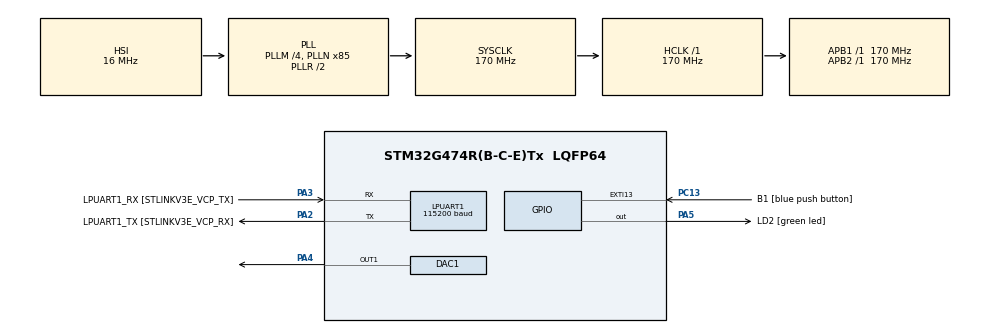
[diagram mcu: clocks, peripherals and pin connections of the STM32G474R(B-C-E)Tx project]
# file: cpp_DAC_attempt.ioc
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DAC1.DAC_SignedFormat-DAC_OUT1=DISABLE
DAC1.DAC_Trigger_OUT1-DAC_OUT1=DAC_TRIGGER_T6_TRGO
Dma.DAC1_CH1.0.Direction=DMA_MEMORY_TO_PERIPH
Dma.DAC1_CH1.0.EventEnable=DISABLE
Dma.DAC1_CH1.0.Instance=DMA1_Channel1
Dma.DAC1_CH1.0.MemDataAlignment=DMA_MDATAALIGN_HALFWORD
Dma.DAC1_CH1.0.MemInc=DMA_MINC_ENABLE
Dma.DAC1_CH1.0.Mode=DMA_CIRCULAR
Dma.DAC1_CH1.0.PeriphDataAlignment=DMA_PDATAALIGN_HALFWORD
Dma.DAC1_CH1.0.PeriphInc=DMA_PINC_DISABLE
Dma.DAC1_CH1.0.Polarity=HAL_DMAMUX_REQ_GEN_RISING
Dma.DAC1_CH1.0.Priority=DMA_PRIORITY_LOW
Dma.DAC1_CH1.0.RequestNumber=1
Dma.DAC1_CH1.0.SignalID=NONE
Dma.DAC1_CH1.0.SyncEnable=DISABLE
Dma.DAC1_CH1.0.SyncPolarity=HAL_DMAMUX_SYNC_NO_EVENT
Dma.DAC1_CH1.0.SyncRequestNumber=1
Dma.DAC1_CH1.0.SyncSignalID=NONE
Dma.Request0=DAC1_CH1
LPUART1.BaudRate=115200
LPUART1.WordLength=UART_WORDLENGTH_8B
Mcu.Family=STM32G4
Mcu.Name=STM32G474R(B-C-E)Tx
Mcu.Package=LQFP64
NVIC.DMA1_Channel1_IRQn=true\:0\:0\:false\:false\:true\:false\:true
NVIC.EXTI15_10_IRQn=true\:0\:0\:false\:false\:true\:true\:true
NVIC.PriorityGroup=NVIC_PRIORITYGROUP_4
NVIC.TIM6_DAC_IRQn=true\:0\:0\:false\:false\:true\:true\:true
PA13.GPIO_Label=T_SWDIO
PA13.Mode=Serial_Wire
PA13.Signal=SYS_JTMS-SWDIO
PA14.GPIO_Label=T_SWCLK
PA14.Mode=Serial_Wire
PA14.Signal=SYS_JTCK-SWCLK
PA2.GPIO_Label=LPUART1_TX [STLINKV3E_VCP_RX]
PA2.Mode=Asynchronous
PA2.Signal=LPUART1_TX
PA3.GPIO_Label=LPUART1_RX [STLINKV3E_VCP_TX]
PA3.Mode=Asynchronous
PA3.Signal=LPUART1_RX
PA4.Signal=COMP_DAC11_group
PA5.GPIO_Label=LD2 [green led]
PA5.Signal=GPIO_Output
PB3.GPIO_Label=T_SWO
PB3.Signal=SYS_JTDO-SWO
PC13.GPIO_Label=B1 [blue push button]
PC13.Signal=GPXTI13
PC14-OSC32_IN.Mode=LSE-External-Oscillator
PC14-OSC32_IN.Signal=RCC_OSC32_IN
PC15-OSC32_OUT.Mode=LSE-External-Oscillator
PC15-OSC32_OUT.Signal=RCC_OSC32_OUT
PF0-OSC_IN.Mode=HSE-External-Oscillator
PF0-OSC_IN.Signal=RCC_OSC_IN
PF1-OSC_OUT.Mode=HSE-External-Oscillator
PF1-OSC_OUT.Signal=RCC_OSC_OUT
ProjectManager.HeapSize=0x200
ProjectManager.StackSize=0x400
ProjectManager.TargetToolchain=STM32CubeIDE
RCC.ADC12Freq_Value=170000000
RCC.ADC345Freq_Value=170000000
RCC.AHBFreq_Value=170000000
RCC.APB1Freq_Value=170000000
RCC.APB1TimFreq_Value=170000000
RCC.APB2Freq_Value=170000000
RCC.APB2TimFreq_Value=170000000
RCC.CortexFreq_Value=170000000
RCC.EXTERNAL_CLOCK_VALUE=12288000
RCC.HCLKFreq_Value=170000000
RCC.HSE_VALUE=24000000
RCC.HSI48_VALUE=48000000
RCC.HSI_VALUE=16000000
RCC.PLLM=RCC_PLLM_DIV4
RCC.PLLN=85
RCC.RTCClockSelection=RCC_RTCCLKSOURCE_LSE
RCC.SYSCLKFreq_VALUE=170000000
RCC.SYSCLKSource=RCC_SYSCLKSOURCE_PLLCLK
RCC.USBFreq_Value=170000000
RCC.VCOOutputFreq_Value=340000000
SH.COMP_DAC11_group.0=DAC1_OUT1,DAC_OUT1
TIM6.TIM_MasterOutputTrigger=TIM_TRGO_UPDATE
VP_SYS_VS_DBSignals.Mode=DisableDeadBatterySignals
VP_TIM6_VS_ClockSourceINT.Mode=Enable_Timer
board=NUCLEO-G474RE

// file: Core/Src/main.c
/* USER CODE BEGIN Header */
/**
  ******************************************************************************
  * @file           : main.c
  * @brief          : Main program body
  ******************************************************************************
  * @attention
  *
  * <h2><center>&copy; Copyright (c) 2021 STMicroelectronics.
  * All rights reserved.</center></h2>
  *
  * This software component is licensed by ST under BSD 3-Clause license,
  * the "License"; You may not use this file except in compliance with the
  * License. You may obtain a copy of the License at:
  *                        opensource.org/licenses/BSD-3-Clause
  *
  ******************************************************************************
  */
/* USER CODE END Header */
#include "main.h"

DAC_HandleTypeDef hdac1;
DMA_HandleTypeDef hdma_dac1_ch1;

UART_HandleTypeDef hlpuart1;

TIM_HandleTypeDef htim6;

/* USER CODE BEGIN PV */
const uint32_t HIGH_ARRAY[12] = {0, 100, 200, 300, 400, 500, 600, 700, 800, 900, 1000, 10000};
const uint16_t LOW_ARRAY[1] = {0};

/* USER CODE END PV */

void SystemClock_Config(void);
static void MX_GPIO_Init(void);
static void MX_DMA_Init(void);
static void MX_LPUART1_UART_Init(void);
static void MX_DAC1_Init(void);
static void MX_TIM6_Init(void);

int main(void)
{

  /* MCU Configuration--------------------------------------------------------*/

  /* Reset of all peripherals, Initializes the Flash interface and the Systick. */
  HAL_Init();

  /* Configure the system clock */
  SystemClock_Config();

  /* Initialize all configured peripherals */
  MX_GPIO_Init();
  MX_DMA_Init();
  MX_LPUART1_UART_Init();
  MX_DAC1_Init();
  MX_TIM6_Init();
  /* USER CODE BEGIN 2 */
  HAL_TIM_Base_Start(&htim6);
  HAL_DAC_Start(&hdac1,DAC_CHANNEL_1);
  HAL_DAC_Start_DMA(&hdac1, DAC_CHANNEL_1, (uint32_t*)HIGH_ARRAY, 32, DAC_ALIGN_12B_R);
  /* USER CODE END 2 */

  /* Infinite loop */
  while (1)
  {

  }
}

void SystemClock_Config(void)
{
  RCC_OscInitTypeDef RCC_OscInitStruct = {0};
  RCC_ClkInitTypeDef RCC_ClkInitStruct = {0};
  RCC_PeriphCLKInitTypeDef PeriphClkInit = {0};

  /** Configure the main internal regulator output voltage
  */
  HAL_PWREx_ControlVoltageScaling(PWR_REGULATOR_VOLTAGE_SCALE1_BOOST);
  /** Initializes the RCC Oscillators according to the specified parameters
  * in the RCC_OscInitTypeDef structure.
  */
  RCC_OscInitStruct.OscillatorType = RCC_OSCILLATORTYPE_HSI;
  RCC_OscInitStruct.HSIState = RCC_HSI_ON;
  RCC_OscInitStruct.HSICalibrationValue = RCC_HSICALIBRATION_DEFAULT;
  RCC_OscInitStruct.PLL.PLLState = RCC_PLL_ON;
  RCC_OscInitStruct.PLL.PLLSource = RCC_PLLSOURCE_HSI;
  RCC_OscInitStruct.PLL.PLLM = RCC_PLLM_DIV4;
  RCC_OscInitStruct.PLL.PLLN = 85;
  RCC_OscInitStruct.PLL.PLLP = RCC_PLLP_DIV2;
  RCC_OscInitStruct.PLL.PLLQ = RCC_PLLQ_DIV2;
  RCC_OscInitStruct.PLL.PLLR = RCC_PLLR_DIV2;
  if (HAL_RCC_OscConfig(&RCC_OscInitStruct) != HAL_OK)
  {
    Error_Handler();
  }
  /** Initializes the CPU, AHB and APB buses clocks
  */
  RCC_ClkInitStruct.ClockType = RCC_CLOCKTYPE_HCLK|RCC_CLOCKTYPE_SYSCLK
                              |RCC_CLOCKTYPE_PCLK1|RCC_CLOCKTYPE_PCLK2;
  RCC_ClkInitStruct.SYSCLKSource = RCC_SYSCLKSOURCE_PLLCLK;
  RCC_ClkInitStruct.AHBCLKDivider = RCC_SYSCLK_DIV1;
  RCC_ClkInitStruct.APB1CLKDivider = RCC_HCLK_DIV1;
  RCC_ClkInitStruct.APB2CLKDivider = RCC_HCLK_DIV1;

  if (HAL_RCC_ClockConfig(&RCC_ClkInitStruct, FLASH_LATENCY_4) != HAL_OK)
  {
    Error_Handler();
  }
  /** Initializes the peripherals clocks
  */
  PeriphClkInit.PeriphClockSelection = RCC_PERIPHCLK_LPUART1;
  PeriphClkInit.Lpuart1ClockSelection = RCC_LPUART1CLKSOURCE_PCLK1;
  if (HAL_RCCEx_PeriphCLKConfig(&PeriphClkInit) != HAL_OK)
  {
    Error_Handler();
  }
}

static void MX_DAC1_Init(void)
{

  DAC_ChannelConfTypeDef sConfig = {0};

  /** DAC Initialization
  */
  hdac1.Instance = DAC1;
  if (HAL_DAC_Init(&hdac1) != HAL_OK)
  {
    Error_Handler();
  }
  /** DAC channel OUT1 config
  */
  sConfig.DAC_HighFrequency = DAC_HIGH_FREQUENCY_INTERFACE_MODE_AUTOMATIC;
  sConfig.DAC_DMADoubleDataMode = DISABLE;
  sConfig.DAC_SignedFormat = DISABLE;
  sConfig.DAC_SampleAndHold = DAC_SAMPLEANDHOLD_DISABLE;
  sConfig.DAC_Trigger = DAC_TRIGGER_T6_TRGO;
  sConfig.DAC_Trigger2 = DAC_TRIGGER_NONE;
  sConfig.DAC_OutputBuffer = DAC_OUTPUTBUFFER_ENABLE;
  sConfig.DAC_ConnectOnChipPeripheral = DAC_CHIPCONNECT_EXTERNAL;
  sConfig.DAC_UserTrimming = DAC_TRIMMING_FACTORY;
  if (HAL_DAC_ConfigChannel(&hdac1, &sConfig, DAC_CHANNEL_1) != HAL_OK)
  {
    Error_Handler();
  }

}

static void MX_LPUART1_UART_Init(void)
{

  hlpuart1.Instance = LPUART1;
  hlpuart1.Init.BaudRate = 115200;
  hlpuart1.Init.WordLength = UART_WORDLENGTH_8B;
  hlpuart1.Init.StopBits = UART_STOPBITS_1;
  hlpuart1.Init.Parity = UART_PARITY_NONE;
  hlpuart1.Init.Mode = UART_MODE_TX_RX;
  hlpuart1.Init.HwFlowCtl = UART_HWCONTROL_NONE;
  hlpuart1.Init.OneBitSampling = UART_ONE_BIT_SAMPLE_DISABLE;
  hlpuart1.Init.ClockPrescaler = UART_PRESCALER_DIV1;
  hlpuart1.AdvancedInit.AdvFeatureInit = UART_ADVFEATURE_NO_INIT;
  if (HAL_UART_Init(&hlpuart1) != HAL_OK)
  {
    Error_Handler();
  }
  if (HAL_UARTEx_SetTxFifoThreshold(&hlpuart1, UART_TXFIFO_THRESHOLD_1_8) != HAL_OK)
  {
    Error_Handler();
  }
  if (HAL_UARTEx_SetRxFifoThreshold(&hlpuart1, UART_RXFIFO_THRESHOLD_1_8) != HAL_OK)
  {
    Error_Handler();
  }
  if (HAL_UARTEx_DisableFifoMode(&hlpuart1) != HAL_OK)
  {
    Error_Handler();
  }

}

static void MX_TIM6_Init(void)
{

  TIM_MasterConfigTypeDef sMasterConfig = {0};

  htim6.Instance = TIM6;
  htim6.Init.Prescaler = 0;
  htim6.Init.CounterMode = TIM_COUNTERMODE_UP;
  htim6.Init.Period = 65535;
  htim6.Init.AutoReloadPreload = TIM_AUTORELOAD_PRELOAD_DISABLE;
  if (HAL_TIM_Base_Init(&htim6) != HAL_OK)
  {
    Error_Handler();
  }
  sMasterConfig.MasterOutputTrigger = TIM_TRGO_UPDATE;
  sMasterConfig.MasterSlaveMode = TIM_MASTERSLAVEMODE_DISABLE;
  if (HAL_TIMEx_MasterConfigSynchronization(&htim6, &sMasterConfig) != HAL_OK)
  {
    Error_Handler();
  }

}

static void MX_DMA_Init(void)
{

  /* DMA controller clock enable */
  __HAL_RCC_DMAMUX1_CLK_ENABLE();
  __HAL_RCC_DMA1_CLK_ENABLE();

  /* DMA interrupt init */
  /* DMA1_Channel1_IRQn interrupt configuration */
  HAL_NVIC_SetPriority(DMA1_Channel1_IRQn, 0, 0);
  HAL_NVIC_EnableIRQ(DMA1_Channel1_IRQn);

}

static void MX_GPIO_Init(void)
{
  GPIO_InitTypeDef GPIO_InitStruct = {0};

  /* GPIO Ports Clock Enable */
  __HAL_RCC_GPIOC_CLK_ENABLE();
  __HAL_RCC_GPIOF_CLK_ENABLE();
  __HAL_RCC_GPIOA_CLK_ENABLE();
  __HAL_RCC_GPIOB_CLK_ENABLE();

  /*Configure GPIO pin Output Level */
  HAL_GPIO_WritePin(LD2_GPIO_Port, LD2_Pin, GPIO_PIN_RESET);

  /*Configure GPIO pin : B1_Pin */
  GPIO_InitStruct.Pin = B1_Pin;
  GPIO_InitStruct.Mode = GPIO_MODE_IT_RISING;
  GPIO_InitStruct.Pull = GPIO_NOPULL;
  HAL_GPIO_Init(B1_GPIO_Port, &GPIO_InitStruct);

  /*Configure GPIO pin : LD2_Pin */
  GPIO_InitStruct.Pin = LD2_Pin;
  GPIO_InitStruct.Mode = GPIO_MODE_OUTPUT_PP;
  GPIO_InitStruct.Pull = GPIO_NOPULL;
  GPIO_InitStruct.Speed = GPIO_SPEED_FREQ_LOW;
  HAL_GPIO_Init(LD2_GPIO_Port, &GPIO_InitStruct);

  /* EXTI interrupt init*/
  HAL_NVIC_SetPriority(EXTI15_10_IRQn, 0, 0);
  HAL_NVIC_EnableIRQ(EXTI15_10_IRQn);

}

void Error_Handler(void)
{
  __disable_irq();
  while (1)
  {
  }
}

/************************ (C) COPYRIGHT STMicroelectronics *****END OF FILE****/
